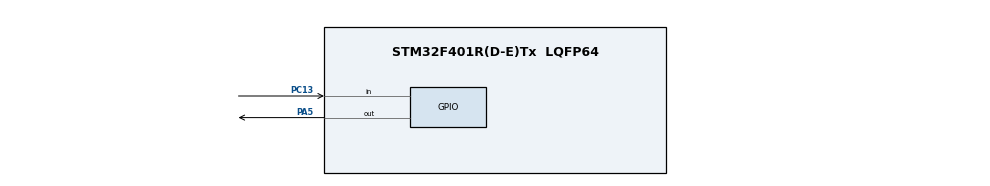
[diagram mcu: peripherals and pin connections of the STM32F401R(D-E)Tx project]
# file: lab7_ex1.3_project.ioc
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Mcu.Family=STM32F4
Mcu.Name=STM32F401R(D-E)Tx
Mcu.Package=LQFP64
NVIC.PriorityGroup=NVIC_PRIORITYGROUP_4
PA5.Signal=GPIO_Output
PC13-ANTI_TAMP.Signal=GPIO_Input
ProjectManager.HeapSize=0x200
ProjectManager.StackSize=0x400
ProjectManager.TargetToolchain=STM32CubeIDE
RCC.AHBFreq_Value=16000000
RCC.APB1Freq_Value=16000000
RCC.APB2Freq_Value=16000000
RCC.CortexFreq_Value=16000000
RCC.HSE_VALUE=25000000
RCC.HSI_VALUE=16000000
RCC.LSE_VALUE=32768
RCC.SYSCLKFreq_VALUE=16000000
RCC.VCOOutputFreq_Value=192000000
board=custom

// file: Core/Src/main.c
/* USER CODE BEGIN Header */
/**
  ******************************************************************************
  * @file           : main.c
  * @brief          : Main program body
  ******************************************************************************
  * @attention
  *
  * <h2><center>&copy; Copyright (c) 2020 STMicroelectronics.
  * All rights reserved.</center></h2>
  *
  * This software component is licensed by ST under BSD 3-Clause license,
  * the "License"; You may not use this file except in compliance with the
  * License. You may obtain a copy of the License at:
  *                        opensource.org/licenses/BSD-3-Clause
  *
  ******************************************************************************
  */
/* USER CODE END Header */

#include "main.h"

void SystemClock_Config(void);
static void MX_GPIO_Init(void);

int main(void)
{

  /* MCU Configuration--------------------------------------------------------*/

  /* Reset of all peripherals, Initializes the Flash interface and the Systick. */

  LL_APB2_GRP1_EnableClock(LL_APB2_GRP1_PERIPH_SYSCFG);
  LL_APB1_GRP1_EnableClock(LL_APB1_GRP1_PERIPH_PWR);

  NVIC_SetPriorityGrouping(NVIC_PRIORITYGROUP_4);

  /* System interrupt init*/

  /* Configure the system clock */
  SystemClock_Config();

  /* Initialize all configured peripherals */
  MX_GPIO_Init();
  /* USER CODE BEGIN 2 */
  LL_GPIO_WriteReg(GPIOA , ODR, LL_GPIO_ReadReg(GPIOA,ODR) | 0x20);
  /* USER CODE END 2 */
  int is_event=0,flag =0 , delay = 2000;
  /* Infinite loop */
  while (1)
  {
	  if((LL_GPIO_ReadReg(GPIOC ,IDR) & 0x2000) == 0x2000)
		  flag = 1;/*flag is for the change in the input between each transition delay  */
	  /*is event is to be flagged during the delay state */

	  LL_mDelay(delay, & flag, & is_event);//this function is a built_in function that provides accurate delay in milliseconds
	  	  	  	  	  	  	  	  	  	  // however i added some modifications within it to enhance the performance of the transition
	  LL_GPIO_WriteReg(GPIOA ,ODR, LL_GPIO_ReadReg(GPIOA,ODR) ^ 0x20);
	  if (is_event == 1)
		  delay = delay >> 1;// this applies the division by 2
	  flag = 0;
	  is_event =0;

  }
}

void SystemClock_Config(void)
{
  LL_FLASH_SetLatency(LL_FLASH_LATENCY_0);

  if(LL_FLASH_GetLatency() != LL_FLASH_LATENCY_0)
  {
  Error_Handler();
  }
  LL_PWR_SetRegulVoltageScaling(LL_PWR_REGU_VOLTAGE_SCALE2);
  LL_RCC_HSI_SetCalibTrimming(16);
  LL_RCC_HSI_Enable();

   /* Wait till HSI is ready */
  while(LL_RCC_HSI_IsReady() != 1)
  {

  }
  LL_RCC_SetAHBPrescaler(LL_RCC_SYSCLK_DIV_1);
  LL_RCC_SetAPB1Prescaler(LL_RCC_APB1_DIV_1);
  LL_RCC_SetAPB2Prescaler(LL_RCC_APB2_DIV_1);
  LL_RCC_SetSysClkSource(LL_RCC_SYS_CLKSOURCE_HSI);

   /* Wait till System clock is ready */
  while(LL_RCC_GetSysClkSource() != LL_RCC_SYS_CLKSOURCE_STATUS_HSI)
  {

  }
  LL_Init1msTick(16000000);
  LL_SetSystemCoreClock(16000000);
  LL_RCC_SetTIMPrescaler(LL_RCC_TIM_PRESCALER_TWICE);
}

static void MX_GPIO_Init(void)
{
  LL_GPIO_InitTypeDef GPIO_InitStruct = {0};

  /* GPIO Ports Clock Enable */
  LL_AHB1_GRP1_EnableClock(LL_AHB1_GRP1_PERIPH_GPIOC);
  LL_AHB1_GRP1_EnableClock(LL_AHB1_GRP1_PERIPH_GPIOA);

  /**/
  LL_GPIO_ResetOutputPin(GPIOA, LL_GPIO_PIN_5);

  /**/
  GPIO_InitStruct.Pin = LL_GPIO_PIN_13;
  GPIO_InitStruct.Mode = LL_GPIO_MODE_INPUT;
  GPIO_InitStruct.Pull = LL_GPIO_PULL_NO;
  LL_GPIO_Init(GPIOC, &GPIO_InitStruct);

  /**/
  GPIO_InitStruct.Pin = LL_GPIO_PIN_5;
  GPIO_InitStruct.Mode = LL_GPIO_MODE_OUTPUT;
  GPIO_InitStruct.Speed = LL_GPIO_SPEED_FREQ_LOW;
  GPIO_InitStruct.OutputType = LL_GPIO_OUTPUT_PUSHPULL;
  GPIO_InitStruct.Pull = LL_GPIO_PULL_NO;
  LL_GPIO_Init(GPIOA, &GPIO_InitStruct);

}

void Error_Handler(void)
{
}

/************************ (C) COPYRIGHT STMicroelectronics *****END OF FILE****/
